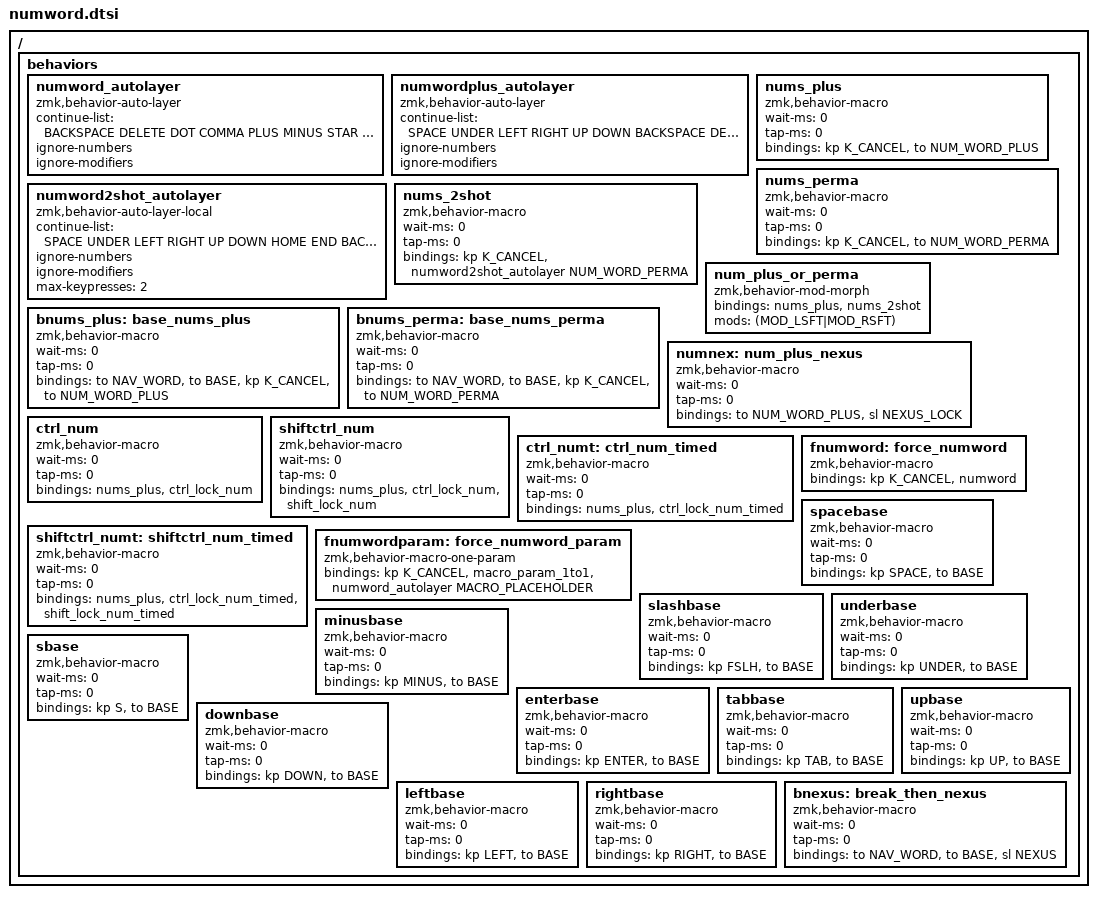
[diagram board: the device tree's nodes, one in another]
/ {
	behaviors {

		numword_autolayer: numword_autolayer {
			compatible = "zmk,behavior-auto-layer";
			#binding-cells = <1>;
			continue-list = <BACKSPACE DELETE DOT COMMA PLUS MINUS STAR FSLH EQUAL CLEAR_AGAIN G>;
			ignore-numbers;
      ignore-modifiers;
		};

		numwordplus_autolayer: numwordplus_autolayer {
			compatible = "zmk,behavior-auto-layer";
			#binding-cells = <1>;
			continue-list = <
        SPACE UNDER LEFT RIGHT UP DOWN BACKSPACE DELETE DOT COMMA PLUS MINUS STAR FSLH BSLH EQUAL CLEAR_AGAIN G COLON SEMI
        C_PREV C_NEXT C_VOL_DN C_VOL_UP C_PLAY_PAUSE
        DQT SQT
        ENTER TAB
        LBKT RBKT
      >;
			ignore-numbers;
      ignore-modifiers;
		};

		numword2shot_autolayer: numword2shot_autolayer {
			compatible = "zmk,behavior-auto-layer-local";
			#binding-cells = <1>;
			continue-list = <
        SPACE UNDER LEFT RIGHT UP DOWN HOME END BACKSPACE DELETE DOT COMMA PLUS MINUS STAR FSLH BSLH EQUAL CLEAR_AGAIN G COLON SEMI
        C_PREV C_NEXT C_VOL_DN C_VOL_UP C_PLAY_PAUSE
        DQT SQT
        ENTER TAB
        LBKT RBKT
        CARET DOLLAR PRCNT LT GT HASH AT
      >;
			ignore-numbers;
      ignore-modifiers;
      max-keypresses = <2>;
		};

		/* numword_with_overlay: numword_with_overlay { */
		/* 	compatible = "zmk,behavior-macro"; */
		/* 	#binding-cells = <0>; */
		/* 	bindings = < */
		/* 	&numword_autolayer NUM_WORD */
		/* 	&numword_autolayer KCAN_OVER */
		/* 	>; */
		/* }; */
		
		/* #define numword numword_autolayer NUM_WORD */
		#define numword to NUM_WORD_PLUS
    #define nsk to_then_sk NUM_WORD_MODDED
		#define numword_plus numwordplus_autolayer NUM_WORD_PLUS


		/* nums: nums { */
		/* 	compatible = "zmk,behavior-macro"; */
		/* 	#binding-cells = <0>; */
		/* 	wait-ms = <0>; */
		/* 	tap-ms = <0>; */
		/* 	bindings = <&sl NUM_WORD>, <&sl NUM_WORD_STICKY>; */
		/* }; */

		nums_plus: nums_plus {
			compatible = "zmk,behavior-macro";
			#binding-cells = <0>;
			wait-ms = <0>;
			tap-ms = <0>;
			/* bindings = <&kp K_CANCEL>, <&to NUM_WORD_PLUS>; aah verður að nota autolayer til að ctrl lock dótið virki */
			/* bindings = <&kp K_CANCEL>, <&numwordplus_autolayer NUM_WORD_PLUS>; hehe þarf það ekki lengur */
			bindings = <&kp K_CANCEL>, <&to NUM_WORD_PLUS>;
		};

		nums_perma: nums_perma {
			compatible = "zmk,behavior-macro";
			#binding-cells = <0>;
			wait-ms = <0>;
			tap-ms = <0>;
			bindings = <&kp K_CANCEL>, <&to NUM_WORD_PERMA>;
		};

		nums_2shot: nums_2shot {
			compatible = "zmk,behavior-macro";
			#binding-cells = <0>;
			wait-ms = <0>;
			tap-ms = <0>;
			bindings = <&kp K_CANCEL>, <&numword2shot_autolayer NUM_WORD_PERMA>;
		};

		num_plus_or_perma: num_plus_or_perma {
			compatible = "zmk,behavior-mod-morph";
			#binding-cells = <0>;
			bindings = <&nums_plus>, <&nums_2shot>;
			mods = <(MOD_LSFT|MOD_RSFT)>;
		};


		bnums_plus: base_nums_plus {
			compatible = "zmk,behavior-macro";
			#binding-cells = <0>;
			wait-ms = <0>;
			tap-ms = <0>;
			/* bindings = <&kp K_CANCEL>, <&to NUM_WORD_PLUS>; aah verður að nota autolayer til að ctrl lock dótið virki */
      /* aah en erum hætt með það svo held ég aftur tími á to */
      /* to NAV_WORD er bara til að brjóta tristate */
			/* bindings = <&to NAV_WORD>, <&to BASE>, <&kp K_CANCEL>, <&numwordplus_autolayer NUM_WORD_PLUS>; */
			bindings = <&to NAV_WORD>, <&to BASE>, <&kp K_CANCEL>, <&to NUM_WORD_PLUS>;
		};
		
		bnums_perma: base_nums_perma {
			compatible = "zmk,behavior-macro";
			#binding-cells = <0>;
			wait-ms = <0>;
			tap-ms = <0>;
			/* bindings = <&kp K_CANCEL>, <&to NUM_WORD_PLUS>; aah verður að nota autolayer til að ctrl lock dótið virki */
      /* aah en erum hætt með það svo held ég aftur tími á to */
      /* to NAV_WORD er bara til að brjóta tristate */
			/* bindings = <&to NAV_WORD>, <&to BASE>, <&kp K_CANCEL>, <&numwordplus_autolayer NUM_WORD_PLUS>; */
			bindings = <&to NAV_WORD>, <&to BASE>, <&kp K_CANCEL>, <&to NUM_WORD_PERMA>;
		};
		
		numnex: num_plus_nexus {
			compatible = "zmk,behavior-macro";
			#binding-cells = <0>;
			wait-ms = <0>;
			tap-ms = <0>;
			bindings = <&to NUM_WORD_PLUS>, <&sl NEXUS_LOCK>; /* verður að nota lock til að dodgea tristates */
		};

		/* num_hold_tap: num_hold_tap { */
		/*   compatible = "zmk,behavior-hold-tap"; */
		/*   #binding-cells = <2>; */
		/*   flavor = "balanced"; */
		/*   tapping-term-ms = <200>; */
		/*   bindings = <&mo>, <&nums>; */
		/* }; */

		/* #define num num_hold_tap NUM_WORD_MODDED 0 */


		ctrl_num: ctrl_num {
			compatible = "zmk,behavior-macro";
			#binding-cells = <0>;
			wait-ms = <0>;
			tap-ms = <0>;
			bindings = <&nums_plus>, <&ctrl_lock_num>;
		};

		shiftctrl_num: shiftctrl_num {
			compatible = "zmk,behavior-macro";
			#binding-cells = <0>;
			wait-ms = <0>;
			tap-ms = <0>;
			bindings = <&nums_plus>, <&ctrl_lock_num>, <&shift_lock_num>;
		};

		ctrl_numt: ctrl_num_timed {
			compatible = "zmk,behavior-macro";
			#binding-cells = <0>;
			wait-ms = <0>;
			tap-ms = <0>;
			bindings = <&nums_plus>, <&ctrl_lock_num_timed>;
		};

		shiftctrl_numt: shiftctrl_num_timed {
			compatible = "zmk,behavior-macro";
			#binding-cells = <0>;
			wait-ms = <0>;
			tap-ms = <0>;
			bindings = <&nums_plus>, <&ctrl_lock_num_timed>, <&shift_lock_num_timed>;
		};

		/* fsl_num: force_sl_num { */
		/* 	compatible = "zmk,behavior-macro"; */
		/* 	#binding-cells = <0>; */
		/* 	bindings = <&kp K_CANCEL>, <&sl NUM_WORD>; */
		/* }; */

		fnumword: force_numword {
			compatible = "zmk,behavior-macro";
			#binding-cells = <0>;
			bindings = <&kp K_CANCEL>, <&numword>;
		};

		fnumwordparam: force_numword_param {
			compatible = "zmk,behavior-macro-one-param";
			#binding-cells = <1>;
			bindings = <&kp K_CANCEL>, <&macro_param_1to1>, <&numword_autolayer MACRO_PLACEHOLDER>;
		};

		/* fnumwordp: force_numword_plus { */
		/* 	compatible = "zmk,behavior-macro"; */
		/* 	#binding-cells = <0>; */
		/* 	bindings = <&kp K_CANCEL>, <&numword_plus>; */
		/* }; */

		/* numword_or_c: numword_or_c { */
		/* 	compatible = "zmk,behavior-mod-morph"; */
		/* 	#binding-cells = <0>; */
		/* 	bindings = <&fnumwordp>, <&kp LS(C)>; */
		/* 	mods = <(MOD_LSFT|MOD_RSFT)>; */
		/* }; */

		spacebase: spacebase {
			compatible = "zmk,behavior-macro";
			#binding-cells = <0>;
			wait-ms = <0>;
			tap-ms = <0>;
			bindings = <&kp SPACE>, <&to BASE>;
		};

		slashbase: slashbase {
			compatible = "zmk,behavior-macro";
			#binding-cells = <0>;
			wait-ms = <0>;
			tap-ms = <0>;
			bindings = <&kp FSLH>, <&to BASE>;
		};

		underbase: underbase {
			compatible = "zmk,behavior-macro";
			#binding-cells = <0>;
			wait-ms = <0>;
			tap-ms = <0>;
			bindings = <&kp UNDER>, <&to BASE>;
		};

		minusbase: minusbase {
			compatible = "zmk,behavior-macro";
			#binding-cells = <0>;
			wait-ms = <0>;
			tap-ms = <0>;
			bindings = <&kp MINUS>, <&to BASE>;
		};

		sbase: sbase {
			compatible = "zmk,behavior-macro";
			#binding-cells = <0>;
			wait-ms = <0>;
			tap-ms = <0>;
			/* bindings = <&kp S>, <&to BASE>, <&sl NEXUS>; */
			bindings = <&kp S>, <&to BASE>;
		};

		enterbase: enterbase {
			compatible = "zmk,behavior-macro";
			#binding-cells = <0>;
			wait-ms = <0>;
			tap-ms = <0>;
			bindings = <&kp ENTER>, <&to BASE>;
		};


		tabbase: tabbase {
			compatible = "zmk,behavior-macro";
			#binding-cells = <0>;
			wait-ms = <0>;
			tap-ms = <0>;
			bindings = <&kp TAB>, <&to BASE>;
		};

		downbase: downbase {
			compatible = "zmk,behavior-macro";
			#binding-cells = <0>;
			wait-ms = <0>;
			tap-ms = <0>;
			bindings = <&kp DOWN>, <&to BASE>;
		};

		upbase: upbase {
			compatible = "zmk,behavior-macro";
			#binding-cells = <0>;
			wait-ms = <0>;
			tap-ms = <0>;
			bindings = <&kp UP>, <&to BASE>;
		};

		leftbase: leftbase {
			compatible = "zmk,behavior-macro";
			#binding-cells = <0>;
			wait-ms = <0>;
			tap-ms = <0>;
			bindings = <&kp LEFT>, <&to BASE>;
		};

		rightbase: rightbase {
			compatible = "zmk,behavior-macro";
			#binding-cells = <0>;
			wait-ms = <0>;
			tap-ms = <0>;
			bindings = <&kp RIGHT>, <&to BASE>;
		};

		/* bnexus_hold: bnexus_hold { */
		/*   compatible = "zmk,behavior-hold-tap"; */
		/*   #binding-cells = <2>; */
		/*   flavor = "balanced"; */
		/*   tapping-term-ms = <200>; */
		/* bindings = <&bmo>, <&bsk_nexus_sk>; */ 
		/*   bindings = <&mo>, <&nexus_sl>; */
		/* }; */

		/* bsym_hold: bsym_hold { */
		/*   compatible = "zmk,behavior-hold-tap"; */
		/*   #binding-cells = <2>; */
		/*   flavor = "balanced"; */
		/*   tapping-term-ms = <200>; */
		/*   bindings = <&bmo>, <&bsk_symbol_sk>; */
		/* }; */

		/* nexus_sl: nexus_sl { */
		/* 	compatible = "zmk,behavior-macro"; */
		/* 	#binding-cells = <0>; */
		/* 	wait-ms = <0>; */
		/* 	tap-ms = <0>; */
		/* 	bindings = <&sl NEXUS>; */
		/* }; */

		bnexus: break_then_nexus {
			compatible = "zmk,behavior-macro";
			#binding-cells = <0>;
			wait-ms = <0>;
			tap-ms = <0>;
			bindings = <&to NAV_WORD>, <&to BASE>, <&sl NEXUS>;
		};

		/* bsk_symbol_sk: bsk_symbol_sk { */
		/* 	compatible = "zmk,behavior-macro"; */
		/* 	#binding-cells = <0>; */
		/* 	wait-ms = <0>; */
		/* 	tap-ms = <0>; */
		/* 	bindings = <&to BASE>, <&sl SYMBOL>; */
		/* }; */


		/* #define bnexus bnexus_hold NEXUS 0 */
		/* #define bsymbol bsym_hold SYMBOL 0 */

		/* N1s: N1s { */
		/* 	compatible = "zmk,behavior-macro"; */
		/* 	#binding-cells = <0>; */
		/* 	wait-ms = <0>; */
		/* 	tap-ms = <0>; */
		/* 	bindings = <&kp N1>, <&oneshot NUM_SPACE>; */
		/* }; */
		/**/
		/* N2s: N2s { */
		/* 	compatible = "zmk,behavior-macro"; */
		/* 	#binding-cells = <0>; */
		/* 	wait-ms = <0>; */
		/* 	tap-ms = <0>; */
		/* 	bindings = <&kp N2>, <&oneshot NUM_SPACE>; */
		/* }; */
		/**/
		/* N3s: N3s { */
		/* 	compatible = "zmk,behavior-macro"; */
		/* 	#binding-cells = <0>; */
		/* 	wait-ms = <0>; */
		/* 	tap-ms = <0>; */
		/* 	bindings = <&kp N3>, <&oneshot NUM_SPACE>; */
		/* }; */
		/**/
		/* N4s: N4s { */
		/* 	compatible = "zmk,behavior-macro"; */
		/* 	#binding-cells = <0>; */
		/* 	wait-ms = <0>; */
		/* 	tap-ms = <0>; */
		/* 	bindings = <&kp N4>, <&oneshot NUM_SPACE>; */
		/* }; */
		/**/
		/* N5s: N5s { */
		/* 	compatible = "zmk,behavior-macro"; */
		/* 	#binding-cells = <0>; */
		/* 	wait-ms = <0>; */
		/* 	tap-ms = <0>; */
		/* 	bindings = <&kp N5>, <&oneshot NUM_SPACE>; */
		/* }; */
		/**/
		/* N6s: N6s { */
		/* 	compatible = "zmk,behavior-macro"; */
		/* 	#binding-cells = <0>; */
		/* 	wait-ms = <0>; */
		/* 	tap-ms = <0>; */
		/* 	bindings = <&kp N6>, <&oneshot NUM_SPACE>; */
		/* }; */
		/**/
		/* N7s: N7s { */
		/* 	compatible = "zmk,behavior-macro"; */
		/* 	#binding-cells = <0>; */
		/* 	wait-ms = <0>; */
		/* 	tap-ms = <0>; */
		/* 	bindings = <&kp N7>, <&oneshot NUM_SPACE>; */
		/* }; */
		/**/
		/* N8s: N8s { */
		/* 	compatible = "zmk,behavior-macro"; */
		/* 	#binding-cells = <0>; */
		/* 	wait-ms = <0>; */
		/* 	tap-ms = <0>; */
		/* 	bindings = <&kp N8>, <&oneshot NUM_SPACE>; */
		/* }; */
		/**/
		/* N9s: N9s { */
		/* 	compatible = "zmk,behavior-macro"; */
		/* 	#binding-cells = <0>; */
		/* 	wait-ms = <0>; */
		/* 	tap-ms = <0>; */
		/* 	bindings = <&kp N9>, <&oneshot NUM_SPACE>; */
		/* }; */
		/**/
		/* N0s: N0s { */
		/* 	compatible = "zmk,behavior-macro"; */
		/* 	#binding-cells = <0>; */
		/* 	wait-ms = <0>; */
		/* 	tap-ms = <0>; */
		/* 	bindings = <&kp N0>, <&oneshot NUM_SPACE>; */
		/* }; */
	};
};
